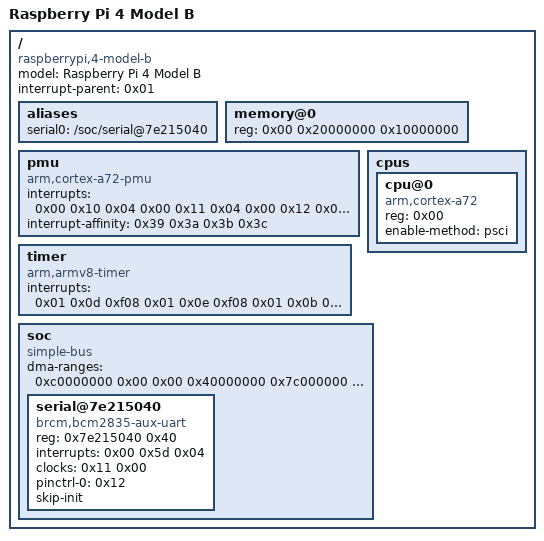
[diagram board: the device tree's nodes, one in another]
/dts-v1/;

/ {
     compatible = "raspberrypi,4-model-b", "brcm,bcm2711";
	model = "Raspberry Pi 4 Model B";
	#address-cells = <0x02>;
	#size-cells = <0x01>;
	interrupt-parent = <0x01>;

     aliases {
		serial0 = "/soc/serial@7e215040";
	};

     memory@0 {
		device_type = "memory";
          /* Tell Linux that only 256MiB of RAM is available starting at 0x20000000 (to avoid collision). */
		reg = <0x00 0x20000000 0x10000000>;
	};

     pmu {
		compatible = "arm,cortex-a72-pmu";
		interrupts = <0x00 0x10 0x04 0x00 0x11 0x04 0x00 0x12 0x04 0x00 0x13 0x04>;
		interrupt-affinity = <0x39 0x3a 0x3b 0x3c>;
	};

	timer {
		compatible = "arm,armv8-timer";
		interrupts = <0x01 0x0d 0xf08 0x01 0x0e 0xf08 0x01 0x0b 0xf08 0x01 0x0a 0xf08>;
	};

	cpus {
		#address-cells = <0x01>;
		#size-cells = <0x00>;

		cpu@0 {
			device_type = "cpu";
			compatible = "arm,cortex-a72";
			reg = <0x00>;
			enable-method = "psci";
		};
	};

     soc {
          compatible = "simple-bus";
		#address-cells = <0x01>;
		#size-cells = <0x01>;
		ranges = <0x7e000000 0x00 0xfe000000 0x1800000 0x7c000000 0x00 0xfc000000 0x2000000 0x40000000 0x00 0xff800000 0x800000>;
		dma-ranges = <0xc0000000 0x00 0x00 0x40000000 0x7c000000 0x00 0xfc000000 0x3800000>;
		phandle = <0x63>;

          serial@7e215040 {
			compatible = "brcm,bcm2835-aux-uart";
			reg = <0x7e215040 0x40>;
			interrupts = <0x00 0x5d 0x04>;
			clocks = <0x11 0x00>;
			status = "okay";
			pinctrl-names = "default";
			pinctrl-0 = <0x12>;
			skip-init;
			phandle = <0x44>;
		};
     };
};
